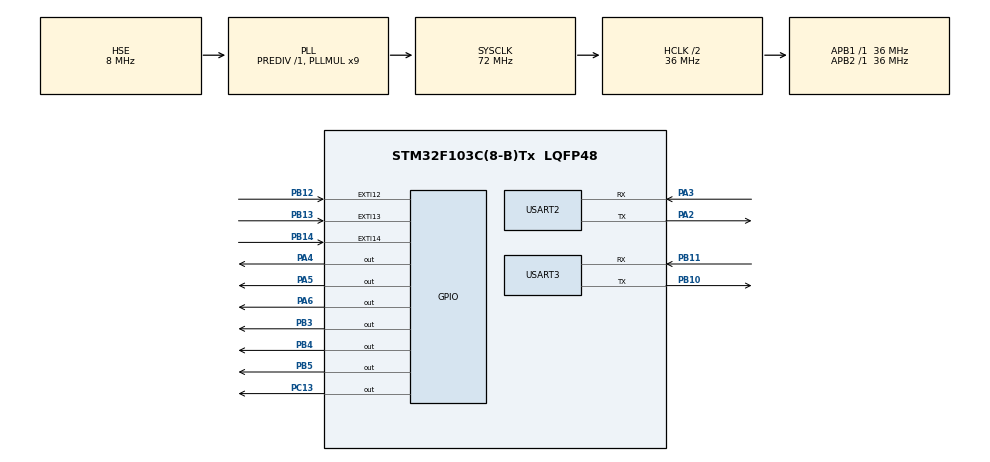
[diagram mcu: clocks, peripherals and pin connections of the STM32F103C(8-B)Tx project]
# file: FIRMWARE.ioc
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Mcu.Family=STM32F1
Mcu.Name=STM32F103C(8-B)Tx
Mcu.Package=LQFP48
NVIC.EXTI15_10_IRQn=true\:0\:0\:false\:false\:true\:true
NVIC.PriorityGroup=NVIC_PRIORITYGROUP_4
NVIC.TIM2_IRQn=true\:0\:0\:false\:false\:true\:true
NVIC.USART3_IRQn=true\:0\:0\:false\:false\:true\:true
PA13.Mode=Serial_Wire
PA13.Signal=SYS_JTMS-SWDIO
PA14.Mode=Serial_Wire
PA14.Signal=SYS_JTCK-SWCLK
PA2.Mode=Asynchronous
PA2.Signal=USART2_TX
PA3.Mode=Asynchronous
PA3.Signal=USART2_RX
PA4.GPIO_Speed=GPIO_SPEED_FREQ_HIGH
PA4.PinState=GPIO_PIN_SET
PA4.Signal=GPIO_Output
PA5.GPIO_Speed=GPIO_SPEED_FREQ_HIGH
PA5.PinState=GPIO_PIN_SET
PA5.Signal=GPIO_Output
PA6.GPIO_Speed=GPIO_SPEED_FREQ_HIGH
PA6.PinState=GPIO_PIN_SET
PA6.Signal=GPIO_Output
PB10.Mode=Asynchronous
PB10.Signal=USART3_TX
PB11.Mode=Asynchronous
PB11.Signal=USART3_RX
PB12.GPIO_ModeDefaultEXTI=GPIO_MODE_IT_RISING_FALLING
PB12.Signal=GPXTI12
PB13.GPIO_ModeDefaultEXTI=GPIO_MODE_IT_RISING_FALLING
PB13.Signal=GPXTI13
PB14.GPIO_ModeDefaultEXTI=GPIO_MODE_IT_RISING_FALLING
PB14.Signal=GPXTI14
PB3.GPIO_Speed=GPIO_SPEED_FREQ_HIGH
PB3.PinState=GPIO_PIN_RESET
PB3.Signal=GPIO_Output
PB4.GPIO_Speed=GPIO_SPEED_FREQ_HIGH
PB4.Signal=GPIO_Output
PB5.GPIO_Speed=GPIO_SPEED_FREQ_HIGH
PB5.Signal=GPIO_Output
PC13-TAMPER-RTC.GPIO_Speed=GPIO_SPEED_FREQ_HIGH
PC13-TAMPER-RTC.Signal=GPIO_Output
PD0-OSC_IN.Mode=HSE-External-Oscillator
PD0-OSC_IN.Signal=RCC_OSC_IN
PD1-OSC_OUT.Mode=HSE-External-Oscillator
PD1-OSC_OUT.Signal=RCC_OSC_OUT
ProjectManager.HeapSize=0x200
ProjectManager.StackSize=0x400
ProjectManager.TargetToolchain=MDK-ARM V5
RCC.AHBCLKDivider=RCC_SYSCLK_DIV2
RCC.AHBFreq_Value=36000000
RCC.APB1Freq_Value=36000000
RCC.APB1TimFreq_Value=36000000
RCC.APB2Freq_Value=36000000
RCC.APB2TimFreq_Value=36000000
RCC.HCLKFreq_Value=36000000
RCC.PLLMUL=RCC_PLL_MUL9
RCC.PLLSourceVirtual=RCC_PLLSOURCE_HSE
RCC.SYSCLKFreq_VALUE=72000000
RCC.SYSCLKSource=RCC_SYSCLKSOURCE_PLLCLK
RCC.USBFreq_Value=72000000
TIM2.AutoReloadPreload=TIM_AUTORELOAD_PRELOAD_ENABLE
TIM2.Period=499
TIM2.Prescaler=36000
USART2.VirtualMode=VM_ASYNC
USART3.VirtualMode=VM_ASYNC
VP_TIM2_VS_ClockSourceINT.Mode=Internal
board=FIRMWARE

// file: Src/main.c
/**
  ******************************************************************************
  * @file           : main.c
  * @brief          : Main program body
  ******************************************************************************
  ** This notice applies to any and all portions of this file
  * that are not between comment pairs USER CODE BEGIN and
  * USER CODE END. Other portions of this file, whether
  * inserted by the user or by software development tools
  * are owned by their respective copyright owners.
  *
  * COPYRIGHT(c) 2018 STMicroelectronics
  *
  * Redistribution and use in source and binary forms, with or without modification,
  * are permitted provided that the following conditions are met:
  *   1. Redistributions of source code must retain the above copyright notice,
  *      this list of conditions and the following disclaimer.
  *   2. Redistributions in binary form must reproduce the above copyright notice,
  *      this list of conditions and the following disclaimer in the documentation
  *      and/or other materials provided with the distribution.
  *   3. Neither the name of STMicroelectronics nor the names of its contributors
  *      may be used to endorse or promote products derived from this software
  *      without specific prior written permission.
  *
  * THIS SOFTWARE IS PROVIDED BY THE COPYRIGHT HOLDERS AND CONTRIBUTORS "AS IS"
  * AND ANY EXPRESS OR IMPLIED WARRANTIES, INCLUDING, BUT NOT LIMITED TO, THE
  * IMPLIED WARRANTIES OF MERCHANTABILITY AND FITNESS FOR A PARTICULAR PURPOSE ARE
  * DISCLAIMED. IN NO EVENT SHALL THE COPYRIGHT HOLDER OR CONTRIBUTORS BE LIABLE
  * FOR ANY DIRECT, INDIRECT, INCIDENTAL, SPECIAL, EXEMPLARY, OR CONSEQUENTIAL
  * DAMAGES (INCLUDING, BUT NOT LIMITED TO, PROCUREMENT OF SUBSTITUTE GOODS OR
  * SERVICES; LOSS OF USE, DATA, OR PROFITS; OR BUSINESS INTERRUPTION) HOWEVER
  * CAUSED AND ON ANY THEORY OF LIABILITY, WHETHER IN CONTRACT, STRICT LIABILITY,
  * OR TORT (INCLUDING NEGLIGENCE OR OTHERWISE) ARISING IN ANY WAY OUT OF THE USE
  * OF THIS SOFTWARE, EVEN IF ADVISED OF THE POSSIBILITY OF SUCH DAMAGE.
  *
  ******************************************************************************
  */
#include "main.h"
#include "stm32f1xx_hal.h"
#include "tim.h"
#include "usart.h"
#include "gpio.h"

/* USER CODE BEGIN Includes */
#include "check_state.h"
#include "commu_uart.h"
#include "relay.h"
/* USER CODE END Includes */

/* USER CODE BEGIN PV */
/* Private variables ---------------------------------------------------------*/
extern bool flag_button_toggle_state;
extern uint16_t byte_state_relay_last;
extern circular_buf_t cbuf1;

/* USER CODE END PV */

void SystemClock_Config(void);

/* USER CODE BEGIN PFP */
/* Private function prototypes -----------------------------------------------*/

/* USER CODE END PFP */

int main(void)
{

  /* MCU Configuration----------------------------------------------------------*/

  /* Reset of all peripherals, Initializes the Flash interface and the Systick. */
  HAL_Init();

  /* Configure the system clock */
  SystemClock_Config();

  /* Initialize all configured peripherals */
  MX_GPIO_Init();
  MX_USART2_UART_Init();
  MX_TIM2_Init();
  MX_USART3_UART_Init();
  /* USER CODE BEGIN 2 */

	/*******************************************************************************/
	/* Start timer 3 interrupt */
   HAL_TIM_Base_Start_IT(&htim2);

	 /* DEBUG */
	 printf("STM32 START ... \r\n");

	 /* communication usart init */
	 COMMU_init();

	/********************************************************************************/
  /* USER CODE END 2 */

  /* Infinite loop */
  while (1)
  {

  /* USER CODE BEGIN 3 */
	/*******************************************************************************/
  if(flag_button_toggle_state == true)
	 {
		 /* if press button then transmition state relay */
		 COMMU_trans_state_relay(DIR_ACTION);
		 /* for debug*/
		 printf("%d\r\n",byte_state_relay_last);
		 /* clean flag*/
		 flag_button_toggle_state = false;
	 }
	 COMMU_get_data_control();

	/*******************************************************************************/

  }
  /* USER CODE END 3 */

}

void SystemClock_Config(void)
{

  RCC_OscInitTypeDef RCC_OscInitStruct;
  RCC_ClkInitTypeDef RCC_ClkInitStruct;

    /**Initializes the CPU, AHB and APB busses clocks
    */
  RCC_OscInitStruct.OscillatorType = RCC_OSCILLATORTYPE_HSE;
  RCC_OscInitStruct.HSEState = RCC_HSE_ON;
  RCC_OscInitStruct.HSEPredivValue = RCC_HSE_PREDIV_DIV1;
  RCC_OscInitStruct.HSIState = RCC_HSI_ON;
  RCC_OscInitStruct.PLL.PLLState = RCC_PLL_ON;
  RCC_OscInitStruct.PLL.PLLSource = RCC_PLLSOURCE_HSE;
  RCC_OscInitStruct.PLL.PLLMUL = RCC_PLL_MUL9;
  if (HAL_RCC_OscConfig(&RCC_OscInitStruct) != HAL_OK)
  {
    _Error_Handler(__FILE__, __LINE__);
  }

    /**Initializes the CPU, AHB and APB busses clocks
    */
  RCC_ClkInitStruct.ClockType = RCC_CLOCKTYPE_HCLK|RCC_CLOCKTYPE_SYSCLK
                              |RCC_CLOCKTYPE_PCLK1|RCC_CLOCKTYPE_PCLK2;
  RCC_ClkInitStruct.SYSCLKSource = RCC_SYSCLKSOURCE_PLLCLK;
  RCC_ClkInitStruct.AHBCLKDivider = RCC_SYSCLK_DIV2;
  RCC_ClkInitStruct.APB1CLKDivider = RCC_HCLK_DIV1;
  RCC_ClkInitStruct.APB2CLKDivider = RCC_HCLK_DIV1;

  if (HAL_RCC_ClockConfig(&RCC_ClkInitStruct, FLASH_LATENCY_2) != HAL_OK)
  {
    _Error_Handler(__FILE__, __LINE__);
  }

    /**Configure the Systick interrupt time
    */
  HAL_SYSTICK_Config(HAL_RCC_GetHCLKFreq()/1000);

    /**Configure the Systick
    */
  HAL_SYSTICK_CLKSourceConfig(SYSTICK_CLKSOURCE_HCLK);

  /* SysTick_IRQn interrupt configuration */
  HAL_NVIC_SetPriority(SysTick_IRQn, 0, 0);
}

void _Error_Handler(char *file, int line)
{
  while(1)
  {
  }
}

/************************ (C) COPYRIGHT STMicroelectronics *****END OF FILE****/
